VERSION ""

NS_ :

BS_:

BU_:

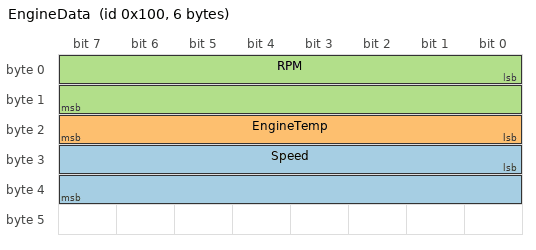
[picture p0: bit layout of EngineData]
BO_ 256 EngineData: 6 Vector__XXX
 SG_ Speed : 24|16@1+ (1,0) [0|250] "km/h" Vector__XXX
 SG_ EngineTemp : 16|8@1+ (1,0) [0|150] "c" Vector__XXX
 SG_ RPM : 0|16@1+ (1,0) [0|8000] "rpm" Vector__XXX

BA_DEF_  "BusType" STRING ;
BA_DEF_DEF_  "BusType" "CAN";
